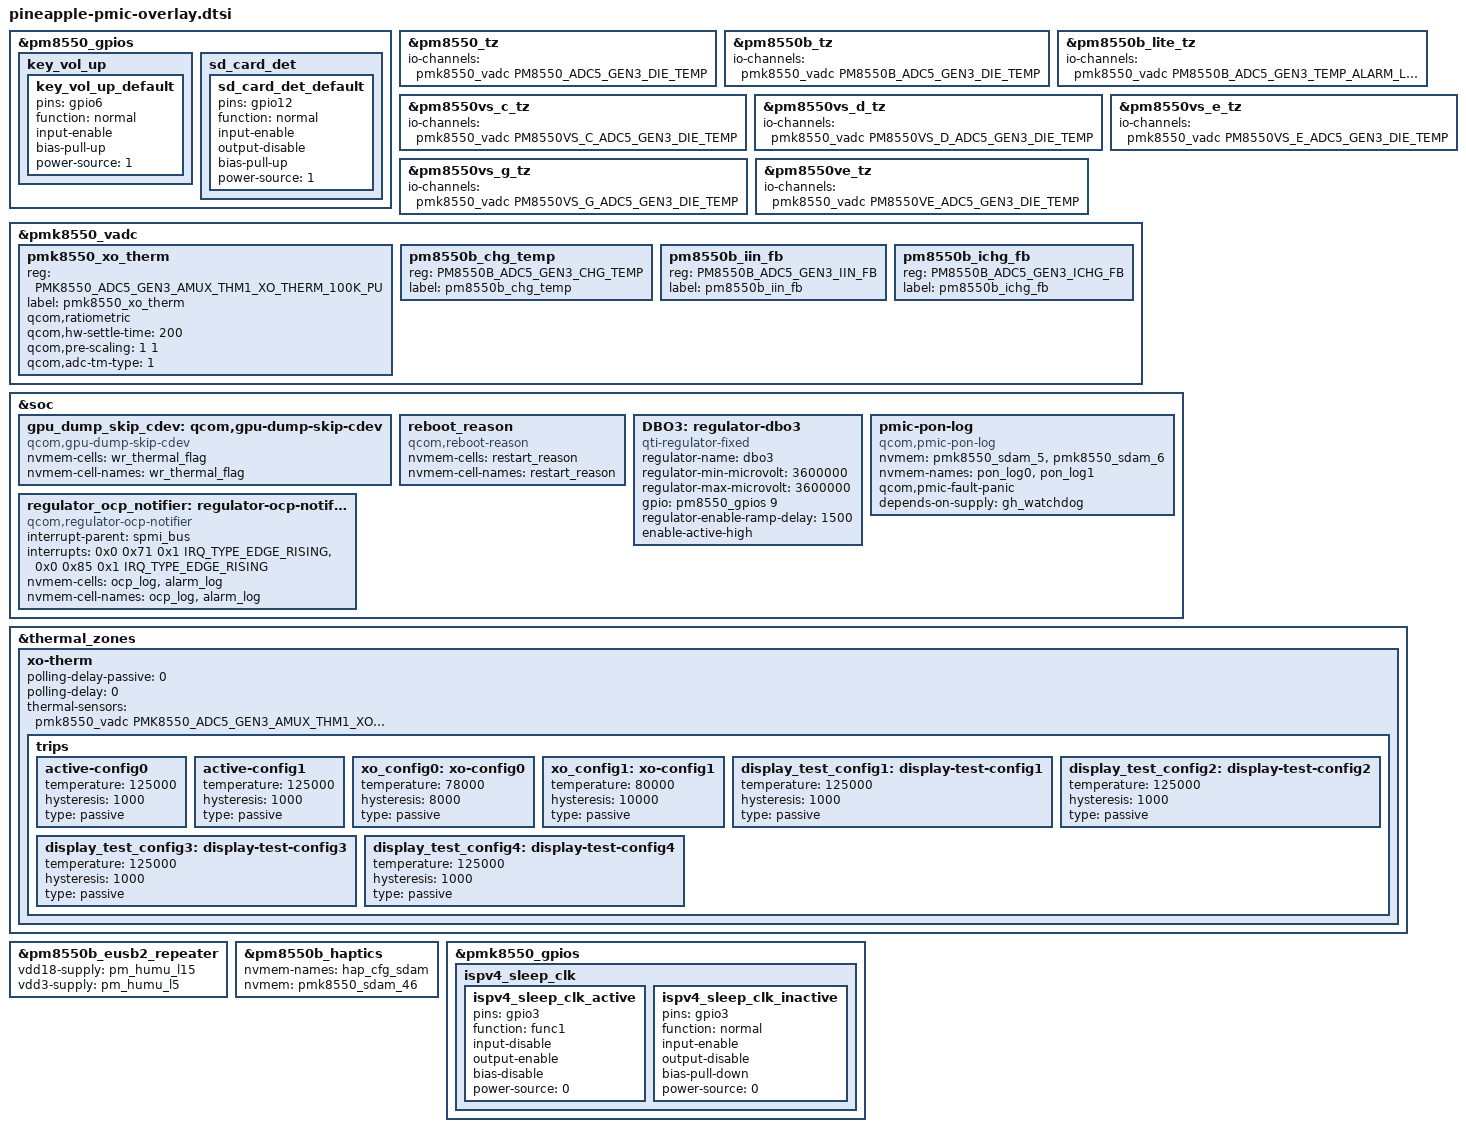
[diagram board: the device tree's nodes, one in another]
#include <dt-bindings/gpio/gpio.h>

#include "pm8010.dtsi"
#include "pm8550.dtsi"
#include "pm8550b.dtsi"
#include "pm8550ve.dtsi"
#include "pm8550vs.dtsi"
#include "pmk8550.dtsi"
#include "pmr735d.dtsi"

&pm8550_gpios {
	key_vol_up {
		key_vol_up_default: key_vol_up_default {
			pins = "gpio6";
			function = "normal";
			input-enable;
			bias-pull-up;
			power-source = <1>;
		};
	};

	sd_card_det {
		sd_card_det_default: sd_card_det_default {
			pins = "gpio12";
			function = "normal";
			input-enable;
			output-disable;
			bias-pull-up;
			power-source = <1>; /* 1.8 V */
		};
	};
};

&pm8550_tz {
	io-channels = <&pmk8550_vadc PM8550_ADC5_GEN3_DIE_TEMP>;
	io-channel-names = "thermal";
};

&pm8550b_tz {
	io-channels = <&pmk8550_vadc PM8550B_ADC5_GEN3_DIE_TEMP>;
	io-channel-names = "thermal";
};

&pm8550b_lite_tz {
	io-channels = <&pmk8550_vadc PM8550B_ADC5_GEN3_TEMP_ALARM_LITE>;
	io-channel-names = "thermal";
};

&pm8550vs_c_tz {
	io-channels = <&pmk8550_vadc PM8550VS_C_ADC5_GEN3_DIE_TEMP>;
	io-channel-names = "thermal";
};

&pm8550vs_d_tz {
	io-channels = <&pmk8550_vadc PM8550VS_D_ADC5_GEN3_DIE_TEMP>;
	io-channel-names = "thermal";
};

&pm8550vs_e_tz {
	io-channels = <&pmk8550_vadc PM8550VS_E_ADC5_GEN3_DIE_TEMP>;
	io-channel-names = "thermal";
};

&pm8550vs_g_tz {
	io-channels = <&pmk8550_vadc PM8550VS_G_ADC5_GEN3_DIE_TEMP>;
	io-channel-names = "thermal";
};

&pm8550ve_tz {
	io-channels = <&pmk8550_vadc PM8550VE_ADC5_GEN3_DIE_TEMP>;
	io-channel-names = "thermal";
};

&pmk8550_vadc {
	pmk8550_xo_therm {
		reg = <PMK8550_ADC5_GEN3_AMUX_THM1_XO_THERM_100K_PU>;
		label = "pmk8550_xo_therm";
		qcom,ratiometric;
		qcom,hw-settle-time = <200>;
		qcom,pre-scaling = <1 1>;
		qcom,adc-tm-type = <1>;
	};

	pm8550b_chg_temp {
		reg = <PM8550B_ADC5_GEN3_CHG_TEMP>;
		label = "pm8550b_chg_temp";
	};

	pm8550b_iin_fb {
		reg = <PM8550B_ADC5_GEN3_IIN_FB>;
		label = "pm8550b_iin_fb";
	};

	pm8550b_ichg_fb {
		reg = <PM8550B_ADC5_GEN3_ICHG_FB>;
		label = "pm8550b_ichg_fb";
	};
};

&soc {
	gpu_dump_skip_cdev: qcom,gpu-dump-skip-cdev {
		compatible = "qcom,gpu-dump-skip-cdev";
		nvmem-cells = <&wr_thermal_flag>;
		nvmem-cell-names = "wr_thermal_flag";
		#cooling-cells = <2>;
	};
};

&thermal_zones {
	xo-therm {
		polling-delay-passive = <0>;
		polling-delay = <0>;
		thermal-sensors = <&pmk8550_vadc PMK8550_ADC5_GEN3_AMUX_THM1_XO_THERM_100K_PU>;
		trips {
			active-config0 {
				temperature = <125000>;
				hysteresis = <1000>;
				type = "passive";
			};

			active-config1 {
				temperature = <125000>;
				hysteresis = <1000>;
				type = "passive";
			};

			xo_config0: xo-config0 {
				temperature = <78000>;
				hysteresis = <8000>;
				type = "passive";
			};

			xo_config1: xo-config1 {
				temperature = <80000>;
				hysteresis = <10000>;
				type = "passive";
			};

			display_test_config1: display-test-config1 {
				temperature = <125000>;
				hysteresis = <1000>;
				type = "passive";
			};

			display_test_config2: display-test-config2 {
				temperature = <125000>;
				hysteresis = <1000>;
				type = "passive";
			};

			display_test_config3: display-test-config3 {
				temperature = <125000>;
				hysteresis = <1000>;
				type = "passive";
			};

			display_test_config4: display-test-config4 {
				temperature = <125000>;
				hysteresis = <1000>;
				type = "passive";
			};
		};
	};
};

&pm8550b_eusb2_repeater {
	vdd18-supply = <&pm_humu_l15>;
	vdd3-supply = <&pm_humu_l5>;
};

&pm8550b_haptics {
	nvmem-names = "hap_cfg_sdam";
	nvmem = <&pmk8550_sdam_46>;
};

&pmk8550_gpios {
	ispv4_sleep_clk {
		ispv4_sleep_clk_active: ispv4_sleep_clk_active {
			pins = "gpio3";
			function = "func1";
			input-disable;
			output-enable;
			bias-disable;
			power-source = <0>;
		};

		ispv4_sleep_clk_inactive: ispv4_sleep_clk_inactive {
			pins = "gpio3";
			function = "normal";
			input-enable;
			output-disable;
			bias-pull-down;
			power-source = <0>;
		};
	};
};

&soc {
	reboot_reason {
		compatible = "qcom,reboot-reason";
		nvmem-cells = <&restart_reason>;
		nvmem-cell-names = "restart_reason";
	};

	DBO3: regulator-dbo3 {
		compatible = "qti-regulator-fixed";
		regulator-name = "dbo3";
		regulator-min-microvolt = <3600000>;
		regulator-max-microvolt = <3600000>;
		gpio = <&pm8550_gpios 9 GPIO_ACTIVE_HIGH>;
		regulator-enable-ramp-delay = <1500>;
		enable-active-high;
	};

	pmic-pon-log {
		compatible = "qcom,pmic-pon-log";
		nvmem = <&pmk8550_sdam_5>, <&pmk8550_sdam_6>;
		nvmem-names = "pon_log0", "pon_log1";
		qcom,pmic-fault-panic;
		depends-on-supply = <&gh_watchdog>;
	};

	regulator_ocp_notifier: regulator-ocp-notifier {
		compatible = "qcom,regulator-ocp-notifier";
		interrupt-parent = <&spmi_bus>;
		interrupts = <0x0 0x71 0x1 IRQ_TYPE_EDGE_RISING>,
			     <0x0 0x85 0x1 IRQ_TYPE_EDGE_RISING>;
		nvmem-cells = <&ocp_log>, <&alarm_log>;
		nvmem-cell-names = "ocp_log", "alarm_log";
	};
};
